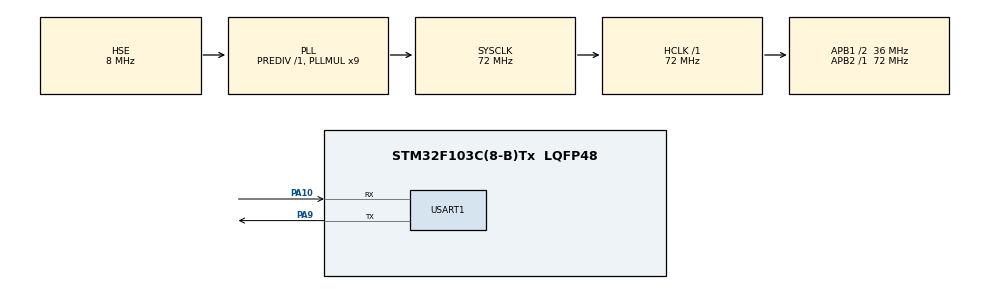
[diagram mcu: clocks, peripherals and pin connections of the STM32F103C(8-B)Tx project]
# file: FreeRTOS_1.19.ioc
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FREERTOS.BinarySemaphores01=myBinarySem01,Dynamic,NULL
FREERTOS.CountingSemaphores01=myCountingSem01,6,Dynamic,NULL
FREERTOS.Queues01=myQueue01,16,uint16_t,0,Dynamic,NULL,NULL
FREERTOS.Tasks01=defaultTask,24,128,StartDefaultTask,Default,NULL,Dynamic,NULL,NULL;myTask02,8,128,StartTask02,Default,NULL,Dynamic,NULL,NULL;myTask03,8,128,StartTask03,Default,NULL,Dynamic,NULL,NULL
FREERTOS.Timers01=myTimer01,Callback01,osTimerPeriodic,Default,NULL,Dynamic,NULL
Mcu.Family=STM32F1
Mcu.Name=STM32F103C(8-B)Tx
Mcu.Package=LQFP48
NVIC.PriorityGroup=NVIC_PRIORITYGROUP_4
NVIC.TIM1_UP_IRQn=true\:15\:0\:false\:false\:true\:false\:false\:true\:true
NVIC.TimeBase=TIM1_UP_IRQn
NVIC.TimeBaseIP=TIM1
NVIC.USART1_IRQn=true\:5\:0\:false\:false\:true\:true\:true\:true\:true
PA10.Mode=Asynchronous
PA10.Signal=USART1_RX
PA13.Mode=Serial_Wire
PA13.Signal=SYS_JTMS-SWDIO
PA14.Mode=Serial_Wire
PA14.Signal=SYS_JTCK-SWCLK
PA9.Mode=Asynchronous
PA9.Signal=USART1_TX
PD0-OSC_IN.Mode=HSE-External-Oscillator
PD0-OSC_IN.Signal=RCC_OSC_IN
PD1-OSC_OUT.Mode=HSE-External-Oscillator
PD1-OSC_OUT.Signal=RCC_OSC_OUT
ProjectManager.HeapSize=0x200
ProjectManager.StackSize=0x400
ProjectManager.TargetToolchain=MDK-ARM V5.32
RCC.AHBFreq_Value=72000000
RCC.APB1CLKDivider=RCC_HCLK_DIV2
RCC.APB1Freq_Value=36000000
RCC.APB1TimFreq_Value=72000000
RCC.APB2Freq_Value=72000000
RCC.APB2TimFreq_Value=72000000
RCC.HCLKFreq_Value=72000000
RCC.PLLMUL=RCC_PLL_MUL9
RCC.PLLSourceVirtual=RCC_PLLSOURCE_HSE
RCC.SYSCLKFreq_VALUE=72000000
RCC.SYSCLKSource=RCC_SYSCLKSOURCE_PLLCLK
RCC.USBFreq_Value=72000000
USART1.VirtualMode=VM_ASYNC
VP_FREERTOS_VS_CMSIS_V2.Mode=CMSIS_V2
VP_SYS_VS_tim1.Mode=TIM1
board=custom

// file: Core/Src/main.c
/* USER CODE BEGIN Header */
/**
  ******************************************************************************
  * @file           : main.c
  * @brief          : Main program body
  ******************************************************************************
  * @attention
  *
  * Copyright (c) 2024 STMicroelectronics.
  * All rights reserved.
  *
  * This software is licensed under terms that can be found in the LICENSE file
  * in the root directory of this software component.
  * If no LICENSE file comes with this software, it is provided AS-IS.
  *
  ******************************************************************************
  */
/* USER CODE END Header */
#include "main.h"
#include "cmsis_os.h"
#include "usart.h"
#include "gpio.h"

void SystemClock_Config(void);
void MX_FREERTOS_Init(void);

int main(void)
{

  /* MCU Configuration--------------------------------------------------------*/

  /* Reset of all peripherals, Initializes the Flash interface and the Systick. */
  HAL_Init();

  /* Configure the system clock */
  SystemClock_Config();

  /* Initialize all configured peripherals */
  MX_GPIO_Init();
  MX_USART1_UART_Init();

  /* Init scheduler */
  osKernelInitialize();

  /* Call init function for freertos objects (in freertos.c) */
  MX_FREERTOS_Init();

  /* Start scheduler */
  osKernelStart();

  /* We should never get here as control is now taken by the scheduler */
  /* Infinite loop */
  while (1)
  {

  }
}

void SystemClock_Config(void)
{
  RCC_OscInitTypeDef RCC_OscInitStruct = {0};
  RCC_ClkInitTypeDef RCC_ClkInitStruct = {0};

  /** Initializes the RCC Oscillators according to the specified parameters
  * in the RCC_OscInitTypeDef structure.
  */
  RCC_OscInitStruct.OscillatorType = RCC_OSCILLATORTYPE_HSE;
  RCC_OscInitStruct.HSEState = RCC_HSE_ON;
  RCC_OscInitStruct.HSEPredivValue = RCC_HSE_PREDIV_DIV1;
  RCC_OscInitStruct.HSIState = RCC_HSI_ON;
  RCC_OscInitStruct.PLL.PLLState = RCC_PLL_ON;
  RCC_OscInitStruct.PLL.PLLSource = RCC_PLLSOURCE_HSE;
  RCC_OscInitStruct.PLL.PLLMUL = RCC_PLL_MUL9;
  if (HAL_RCC_OscConfig(&RCC_OscInitStruct) != HAL_OK)
  {
    Error_Handler();
  }

  /** Initializes the CPU, AHB and APB buses clocks
  */
  RCC_ClkInitStruct.ClockType = RCC_CLOCKTYPE_HCLK|RCC_CLOCKTYPE_SYSCLK
                              |RCC_CLOCKTYPE_PCLK1|RCC_CLOCKTYPE_PCLK2;
  RCC_ClkInitStruct.SYSCLKSource = RCC_SYSCLKSOURCE_PLLCLK;
  RCC_ClkInitStruct.AHBCLKDivider = RCC_SYSCLK_DIV1;
  RCC_ClkInitStruct.APB1CLKDivider = RCC_HCLK_DIV2;
  RCC_ClkInitStruct.APB2CLKDivider = RCC_HCLK_DIV1;

  if (HAL_RCC_ClockConfig(&RCC_ClkInitStruct, FLASH_LATENCY_2) != HAL_OK)
  {
    Error_Handler();
  }
}

void HAL_TIM_PeriodElapsedCallback(TIM_HandleTypeDef *htim)
{
  if (htim->Instance == TIM1) {
    HAL_IncTick();
  }
}

void Error_Handler(void)
{
  __disable_irq();
  while (1)
  {
  }
}

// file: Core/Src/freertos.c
/* USER CODE BEGIN Header */
/**
  ******************************************************************************
  * File Name          : freertos.c
  * Description        : Code for freertos applications
  ******************************************************************************
  * @attention
  *
  * Copyright (c) 2024 STMicroelectronics.
  * All rights reserved.
  *
  * This software is licensed under terms that can be found in the LICENSE file
  * in the root directory of this software component.
  * If no LICENSE file comes with this software, it is provided AS-IS.
  *
  ******************************************************************************
  */
/* USER CODE END Header */

#include "FreeRTOS.h"
#include "task.h"
#include "main.h"
#include "cmsis_os.h"

/* USER CODE BEGIN Includes */
#include <stdio.h>
#include <string.h>
/* USER CODE END Includes */

/* Definitions for defaultTask */
osThreadId_t defaultTaskHandle;
const osThreadAttr_t defaultTask_attributes = {
  .name = "defaultTask",
  .stack_size = 128 * 4,
  .priority = (osPriority_t) osPriorityNormal,
};
/* Definitions for myTask02 */
osThreadId_t myTask02Handle;
const osThreadAttr_t myTask02_attributes = {
  .name = "myTask02",
  .stack_size = 128 * 4,
  .priority = (osPriority_t) osPriorityLow,
};
/* Definitions for myTask03 */
osThreadId_t myTask03Handle;
const osThreadAttr_t myTask03_attributes = {
  .name = "myTask03",
  .stack_size = 128 * 4,
  .priority = (osPriority_t) osPriorityLow,
};
/* Definitions for myQueue01 */
osMessageQueueId_t myQueue01Handle;
const osMessageQueueAttr_t myQueue01_attributes = {
  .name = "myQueue01"
};
/* Definitions for myTimer01 */
osTimerId_t myTimer01Handle;
const osTimerAttr_t myTimer01_attributes = {
  .name = "myTimer01"
};
/* Definitions for myBinarySem01 */
osSemaphoreId_t myBinarySem01Handle;
const osSemaphoreAttr_t myBinarySem01_attributes = {
  .name = "myBinarySem01"
};
/* Definitions for myCountingSem01 */
osSemaphoreId_t myCountingSem01Handle;
const osSemaphoreAttr_t myCountingSem01_attributes = {
  .name = "myCountingSem01"
};

void StartDefaultTask(void *argument);
void StartTask02(void *argument);
void StartTask03(void *argument);
void Callback01(void *argument);

void MX_FREERTOS_Init(void); /* (MISRA C 2004 rule 8.1) */

void MX_FREERTOS_Init(void) {

  /* Create the semaphores(s) */
  /* creation of myBinarySem01 */
  myBinarySem01Handle = osSemaphoreNew(1, 0, &myBinarySem01_attributes);

  /* creation of myCountingSem01 */
  myCountingSem01Handle = osSemaphoreNew(6, 6, &myCountingSem01_attributes);

  /* Create the timer(s) */
  /* creation of myTimer01 */
  myTimer01Handle = osTimerNew(Callback01, osTimerPeriodic, NULL, &myTimer01_attributes);

  /* Create the queue(s) */
  /* creation of myQueue01 */
  myQueue01Handle = osMessageQueueNew (16, sizeof(uint16_t), &myQueue01_attributes);

  /* Create the thread(s) */
  /* creation of defaultTask */
  defaultTaskHandle = osThreadNew(StartDefaultTask, NULL, &defaultTask_attributes);

  /* creation of myTask02 */
  myTask02Handle = osThreadNew(StartTask02, NULL, &myTask02_attributes);

  /* creation of myTask03 */
  myTask03Handle = osThreadNew(StartTask03, NULL, &myTask03_attributes);

}

void StartDefaultTask(void *argument)
{
  /* USER CODE BEGIN StartDefaultTask */
	osStatus_t result;

  /* Infinite loop */
  for(;;)
  {
		result = osSemaphoreAcquire(myBinarySem01Handle,10);
		if(result == osOK)
		{
			printf("osOKokokok\r\n");//获取成功
		}else
		{
			printf("osnono\r\n");//获取失败
		}
    osDelay(1);
  }
  /* USER CODE END StartDefaultTask */
}

void StartTask02(void *argument)
{
  /* USER CODE BEGIN StartTask02 */
    osStatus_t result;
    uint8_t dat[10]={0};
    uint8_t *pro;
    result= osTimerStart(myTimer01Handle,1000);
    if(result == osOK)
    {
        printf("osOK\r\n");//启动成功
    }else
    {
        printf("NO\r\n");//启动失败
    }

  /* Infinite loop */
  for(;;)
  {

    osDelay(10);
  }
  /* USER CODE END StartTask02 */
}

void StartTask03(void *argument)
{
  /* USER CODE BEGIN StartTask03 */
  /* Infinite loop */
/* USER CODE BEGIN StartTask02 */

  /* Infinite loop */
  for(;;)
  {
//		result= osMessageQueueGet(myQueue01Handle,dat,pro,10);
//		if(result == osOK)
//		{
//			printf("%s\r\n",dat);//接受成功
//		}else
//		{
//			printf("osMENO\r\n");//接受失败
//		}
    osDelay(1);
  }

  /* USER CODE END StartTask03 */
}

/* Callback01 function */
void Callback01(void *argument)
{
  /* USER CODE BEGIN Callback01 */
//	static int i=0;
//	i++;
//	printf("Hi%d\r\n",i);

  /* USER CODE END Callback01 */
}
